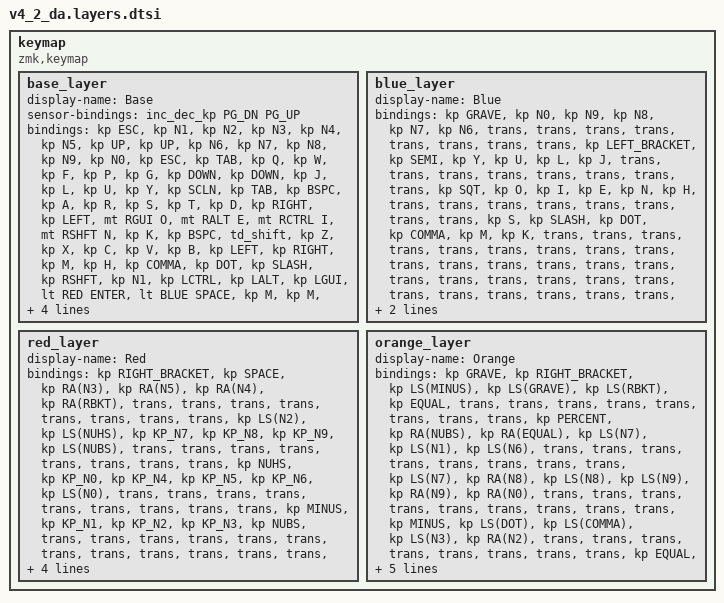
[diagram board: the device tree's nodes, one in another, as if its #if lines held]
/*
 * The layer tables of the DA MonoTypist, generated by tools/gen-keymap.mjs from layout/da.json.
 * Do not edit this file: change layout/da.json and run "node tools/gen-keymap.mjs".
 */

keymap {
    compatible = "zmk,keymap";

    base_layer {
        display-name = "Base";
        sensor-bindings = <&inc_dec_kp PG_DN PG_UP>;
        bindings = <
#if SIMPLE_MODE == 1
            &kp ESC        &kp N1         &kp N2         &kp N3         &kp N4         &kp N5         &kp UP         &kp UP         &kp N6         &kp N7         &kp N8         &kp N9         &kp N0         &kp ESC
#else
            &kp ESC        &kp C_AL_CALC  &kp LG(DOT)    &kp LS(LG(S))  &mac_git       &kp LG(V)      &kp UP         &kp UP         &kp N6         &kp N7         &kp N8         &kp N9         &kp N0         &kp ESC
#endif
            &kp TAB        &kp Q          &kp W          &kp F          &kp P          &kp G          &kp DOWN       &kp DOWN       &kp J          &kp L          &kp U          &kp Y          &kp SCLN       &kp TAB
            &kp BSPC       &kp A          &kp R          &kp S          &kp T          &kp D          &kp RIGHT      &kp LEFT       &mt RGUI O     &mt RALT E     &mt RCTRL I    &mt RSHFT N    &kp K          &kp BSPC
            &td_shift      &kp Z          &kp X          &kp C          &kp V          &kp B          &kp LEFT       &kp RIGHT      &kp M          &kp H          &kp COMMA      &kp DOT        &kp SLASH      &kp RSHFT
            &kp N1         &kp LCTRL      &kp LALT       &kp LGUI       &lt RED ENTER  &lt BLUE SPACE &kp M          &kp M          &kp N9         &kp N8         &kp RGUI       &kp BSPC       &lt NAV SPACE  &kp N0
            &kp N4         &kp N5         &kp N6         &kp N7         &kp N8         &lt ORANGE DEL &kp N9         &kp N1         &kp N5         &kp N4         &kp N3         &kp N2         &kp LSHFT      &kp N6
        >;
    };

    blue_layer {
        display-name = "Blue";
        bindings = <
            &kp GRAVE        &kp N0           &kp N9           &kp N8           &kp N7           &kp N6           &trans           &trans           &trans           &trans           &trans           &trans           &trans           &trans
            &kp LEFT_BRACKET &kp SEMI         &kp Y            &kp U            &kp L            &kp J            &trans           &trans           &trans           &trans           &trans           &trans           &trans           &trans
            &kp SQT          &kp O            &kp I            &kp E            &kp N            &kp H            &trans           &trans           &trans           &trans           &trans           &trans           &trans           &trans
            &kp S            &kp SLASH        &kp DOT          &kp COMMA        &kp M            &kp K            &trans           &trans           &trans           &trans           &trans           &trans           &trans           &trans
            &trans           &trans           &trans           &trans           &trans           &trans           &trans           &trans           &trans           &trans           &trans           &trans           &trans           &trans
            &trans           &trans           &trans           &trans           &trans           &trans           &trans           &trans           &trans           &trans           &trans           &trans           &trans           &trans
        >;
    };

    red_layer {
        display-name = "Red";
        bindings = <
            &kp RIGHT_BRACKET &kp SPACE         &kp RA(N3)        &kp RA(N5)        &kp RA(N4)        &kp RA(RBKT)      &trans            &trans            &trans            &trans            &trans            &trans            &trans            &trans
            &kp LS(N2)        &kp LS(NUHS)      &kp KP_N7         &kp KP_N8         &kp KP_N9         &kp LS(NUBS)      &trans            &trans            &trans            &trans            &trans            &trans            &trans            &trans
            &kp NUHS          &kp KP_N0         &kp KP_N4         &kp KP_N5         &kp KP_N6         &kp LS(N0)        &trans            &trans            &trans            &trans            &trans            &trans            &trans            &trans
            &trans            &kp MINUS         &kp KP_N1         &kp KP_N2         &kp KP_N3         &kp NUBS          &trans            &trans            &trans            &trans            &trans            &trans            &trans            &trans
            &trans            &trans            &trans            &trans            &trans            &trans            &trans            &trans            &trans            &trans            &trans            &trans            &trans            &trans
            &trans            &trans            &trans            &trans            &trans            &trans            &trans            &trans            &trans            &trans            &trans            &trans            &trans            &trans
        >;
    };

    orange_layer {
        display-name = "Orange";
        bindings = <
            &kp GRAVE         &kp RIGHT_BRACKET &kp LS(MINUS)     &kp LS(GRAVE)     &kp LS(RBKT)      &kp EQUAL         &trans            &trans            &trans            &trans            &trans            &trans            &trans            &trans
            &kp PERCENT       &kp RA(NUBS)      &kp RA(EQUAL)     &kp LS(N7)        &kp LS(N1)        &kp LS(N6)        &trans            &trans            &trans            &trans            &trans            &trans            &trans            &trans
            &kp LS(N7)        &kp RA(N8)        &kp LS(N8)        &kp LS(N9)        &kp RA(N9)        &kp RA(N0)        &trans            &trans            &trans            &trans            &trans            &trans            &trans            &trans
            &trans            &kp MINUS         &kp LS(DOT)       &kp LS(COMMA)     &kp LS(N3)        &kp RA(N2)        &trans            &trans            &trans            &trans            &trans            &trans            &trans            &trans
            &kp EQUAL         &trans            &trans            &trans            &trans            &trans            &trans            &trans            &trans            &trans            &trans            &trans            &trans            &trans
            &trans            &trans            &trans            &trans            &trans            &trans            &trans            &trans            &trans            &trans            &trans            &trans            &trans            &trans
        >;
    };
};
